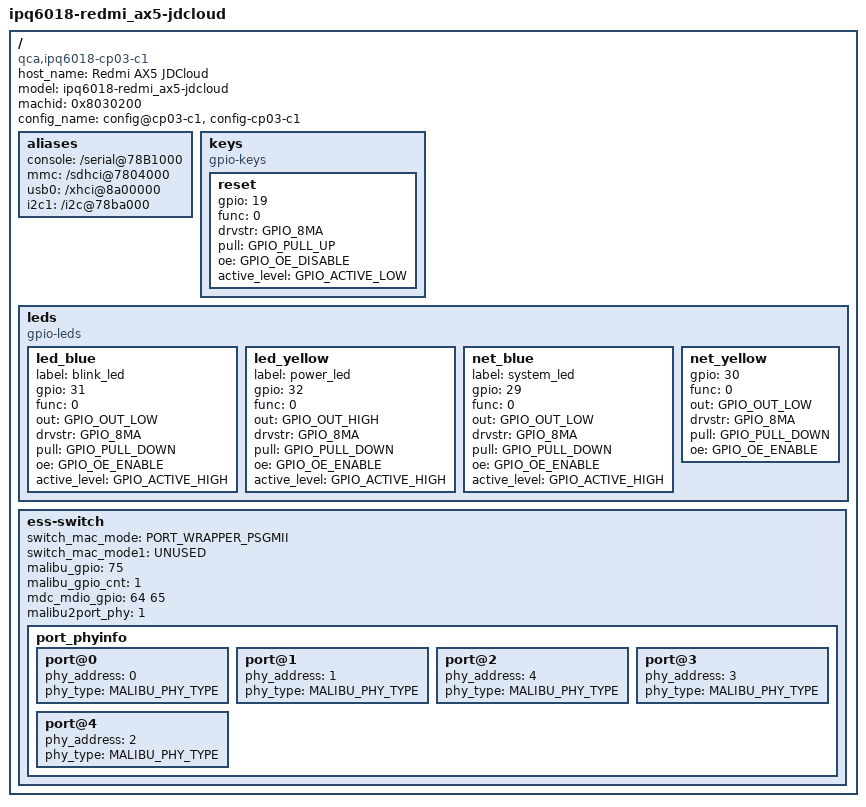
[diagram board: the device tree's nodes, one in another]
/*
 * Copyright (c) 2019, The Linux Foundation. All rights reserved.
 *
 * This program is free software; you can redistribute it and/or modify
 * it under the terms of the GNU General Public License version 2 and
 * only version 2 as published by the Free Software Foundation.
 *
 * This program is distributed in the hope that it will be useful,
 * but WITHOUT ANY WARRANTY; without even the implied warranty of
 * MERCHANTABILITY or FITNESS FOR A PARTICULAR PURPOSE.  See the
 * GNU General Public License for more details.
 */

/dts-v1/;
#include "ipq6018-soc.dtsi"
/ {
	host_name = "Redmi AX5 JDCloud";
	model = "ipq6018-redmi_ax5-jdcloud";
	compatible = "qca,ipq6018-cp03-c1", "qca,ipq6018";
	machid = <0x8030200>;
	config_name = "config@cp03-c1", "config-cp03-c1";

	aliases {
		console = "/serial@78B1000";
		mmc = "/sdhci@7804000";
		usb0 = "/xhci@8a00000";
		i2c1 = "/i2c@78ba000";
	};

	keys {
		compatible = "gpio-keys";

		reset {
			gpio = <19>;
			func = <0>;
			drvstr = <GPIO_8MA>;
			pull = <GPIO_PULL_UP>;
			oe = <GPIO_OE_DISABLE>;
			active_level = <GPIO_ACTIVE_LOW>;
		};
	};

	leds {
		compatible = "gpio-leds";

		led_blue {
			label = "blink_led";
			gpio = <31>;
			func = <0>;
			out = <GPIO_OUT_LOW>;
			drvstr = <GPIO_8MA>;
			pull = <GPIO_PULL_DOWN>;
			oe = <GPIO_OE_ENABLE>;
			active_level = <GPIO_ACTIVE_HIGH>;
		};

		led_yellow {
			label = "power_led";
			gpio = <32>;
			func = <0>;
			out = <GPIO_OUT_HIGH>;
			drvstr = <GPIO_8MA>;
			pull = <GPIO_PULL_DOWN>;
			oe = <GPIO_OE_ENABLE>;
			active_level = <GPIO_ACTIVE_HIGH>;
		};

		net_blue {
			label = "system_led";
			gpio = <29>;
			func = <0>;
			out = <GPIO_OUT_LOW>;
			drvstr = <GPIO_8MA>;
			pull = <GPIO_PULL_DOWN>;
			oe = <GPIO_OE_ENABLE>;
			active_level = <GPIO_ACTIVE_HIGH>;
		};

		net_yellow {
			gpio = <30>;
			func = <0>;
			out = <GPIO_OUT_LOW>;
			drvstr = <GPIO_8MA>;
			pull = <GPIO_PULL_DOWN>;
			oe = <GPIO_OE_ENABLE>;
		};
	};

	ess-switch {
		switch_mac_mode = <PORT_WRAPPER_PSGMII>;
		switch_mac_mode1 = <UNUSED>;
		malibu_gpio = <75>;
		malibu_gpio_cnt = <1>;
		mdc_mdio_gpio = <64 65>;
		malibu2port_phy = <1>;
		port_phyinfo {
			port@0 {
				phy_address = <0>;
				phy_type = <MALIBU_PHY_TYPE>;
			};
			port@1 {
				phy_address = <1>;
				phy_type = <MALIBU_PHY_TYPE>;
			};
			port@2 {
				phy_address = <4>;
				phy_type = <MALIBU_PHY_TYPE>;
			};
			port@3 {
				phy_address = <3>;
				phy_type = <MALIBU_PHY_TYPE>;
			};
			port@4 {
				phy_address = <2>;
				phy_type = <MALIBU_PHY_TYPE>;
			};
		};
	};
};
